# moondancer register map
Vendor: luna-soc
Registers are 8-bit, read-write, reset 0x0 unless marked. A register's access mark holds for its fields unless they carry their own. Offsets are from the block's base; [hi:lo] are bit positions; {n}, {i} and the like mark numbered series.

## info
Base 0xF0001500
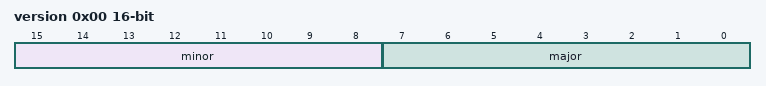
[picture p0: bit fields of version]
0x00 version 16-bit — Version register major : Contains the Cynthion hardware major revision number. minor : Contains the Cynthion hardware minor revision number.
  [15:8] minor ro, [7:0] major ro

## user0
Base 0xF0001600
0x00 Mode — Mode register. This :class:`csr.Register` contains an array of ``pin_count`` read/write fields. Each field is 2-bit wide and its possible values are defined by the :class:`PinMode` enumeration. If ``pin_count`` is 8, then the register has the following fields: .. bitfield:: :bits: 16 [ { "name": "pin[0]", "bits": 2, "attr": "RW" }, { "name": "pin[1]", "bits": 2, "attr": "RW" }, { "name": "pin[2]", "bits": 2, "attr": "RW" }, { "name": "pin[3]", "bits": 2, "attr": "RW" }, { "name": "pin[4]", "bits": 2, "attr": "RW" }, { "name": "pin[5]", "bits": 2, "attr": "RW" }, { "name": "pin[6]", "bits": 2, "attr": "RW" }, { "name": "pin[7]", "bits": 2, "attr": "RW" }, ] Parameters ---------- pin_count : :class:`int` Number of GPIO pins.
  [1:0] pin_0
0x01 Input — Input register. This :class:`csr.Register` contains an array of ``pin_count`` read-only fields. Each field is 1-bit wide and driven by the input of its associated pin in the :attr:`Peripheral.pins` array. Values sampled from pin inputs go through :attr:`Peripheral.input_stages` synchronization stages (on a rising edge of ``ClockSignal("sync")``) before reaching the register. If ``pin_count`` is 8, then the register has the following fields: .. bitfield:: :bits: 8 [ { "name": "pin[0]", "bits": 1, "attr": "R" }, { "name": "pin[1]", "bits": 1, "attr": "R" }, { "name": "pin[2]", "bits": 1, "attr": "R" }, { "name": "pin[3]", "bits": 1, "attr": "R" }, { "name": "pin[4]", "bits": 1, "attr": "R" }, { "name": "pin[5]", "bits": 1, "attr": "R" }, { "name": "pin[6]", "bits": 1, "attr": "R" }, { "name": "pin[7]", "bits": 1, "attr": "R" }, ] Parameters ---------- pin_count : :class:`int` Number of GPIO pins.
  [0] pin_0 ro
0x02 Output — Output register. This :class:`csr.Register` contains an array of ``pin_count`` read/write fields. Each field is 1-bit wide and drives the output of its associated pin in the :attr:`Peripheral.pins` array, depending on its associated :class:`~Peripheral.Mode` field. If ``pin_count`` is 8, then the register has the following fields: .. bitfield:: :bits: 8 [ { "name": "pin[0]", "bits": 1, "attr": "RW" }, { "name": "pin[1]", "bits": 1, "attr": "RW" }, { "name": "pin[2]", "bits": 1, "attr": "RW" }, { "name": "pin[3]", "bits": 1, "attr": "RW" }, { "name": "pin[4]", "bits": 1, "attr": "RW" }, { "name": "pin[5]", "bits": 1, "attr": "RW" }, { "name": "pin[6]", "bits": 1, "attr": "RW" }, { "name": "pin[7]", "bits": 1, "attr": "RW" }, ] Parameters ---------- pin_count : :class:`int` Number of GPIO pins.
  [0] pin_0
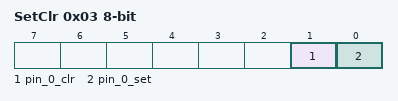
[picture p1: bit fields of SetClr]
0x03 SetClr — Output set/clear register. This :class:`csr.Register` contains an array of ``pin_count`` write-only fields. Each field is 2-bit wide; writing it can modify its associated :class:`~Peripheral.Output` field as a side-effect. If ``pin_count`` is 8, then the register has the following fields: .. bitfield:: :bits: 16 [ { "name": "pin[0]", "bits": 2, "attr": "W" }, { "name": "pin[1]", "bits": 2, "attr": "W" }, { "name": "pin[2]", "bits": 2, "attr": "W" }, { "name": "pin[3]", "bits": 2, "attr": "W" }, { "name": "pin[4]", "bits": 2, "attr": "W" }, { "name": "pin[5]", "bits": 2, "attr": "W" }, { "name": "pin[6]", "bits": 2, "attr": "W" }, { "name": "pin[7]", "bits": 2, "attr": "W" }, ] - Writing `0b01` to a field sets its associated :class:`~Peripheral.Output` field. - Writing `0b10` to a field clears its associated :class:`~Peripheral.Output` field. - Writing `0b00` or `0b11` to a field has no side-effect. Parameters ---------- pin_count : :class:`int` Number of GPIO pins.
  [1] pin_0_clr wo, [0] pin_0_set wo
